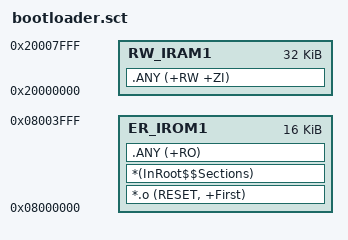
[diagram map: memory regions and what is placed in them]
; ==========================================================
; Scatter File for Bootloader (STM32F303CBT6)
; Занимает Блок 0: 16 КБ (0x0800 0000 - 0x0800 3FFF)
; ==========================================================

LR_IROM1 0x08000000 0x00004000  ; 16 КБ Flash для загрузчика
{
    ER_IROM1 0x08000000 0x00004000
    {
        *.o (RESET, +First)       ; Таблица векторов прерываний загрузчика
        *(InRoot$$Sections)       ; Секции инициализации (__main, __scatterload)
        .ANY (+RO)                ; Код и константы загрузчика
    }
    
    RW_IRAM1 0x20000000 0x00008000  ; 32 КБ RAM (Загрузчик использует всю доступную RAM)
    {
        .ANY (+RW +ZI)
    }
}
